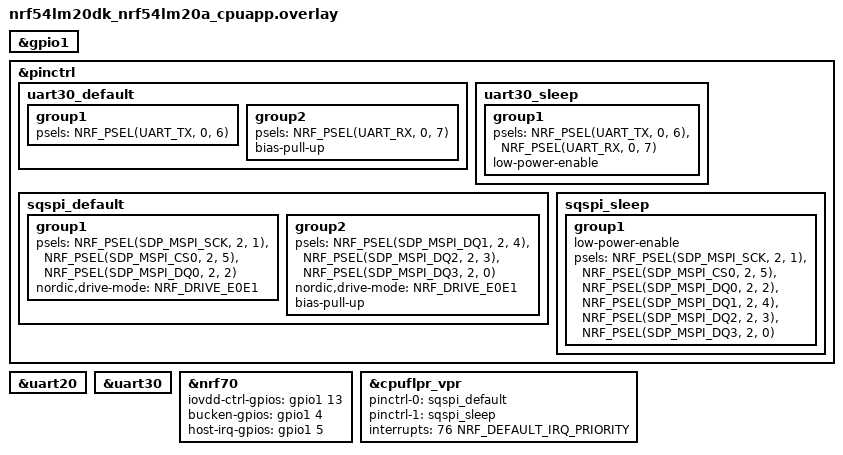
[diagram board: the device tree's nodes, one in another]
/*
 * Copyright (c) 2025 Nordic Semiconductor
 *
 * SPDX-License-Identifier: LicenseRef-Nordic-5-Clause
 */

/* APP core overlay - GPIO pins configuration for nRF70 */


&gpio1 {
	status = "okay";
};

&pinctrl {
	uart30_default: uart30_default {
		group1 {
			psels = <NRF_PSEL(UART_TX, 0, 6)>;
		};

		group2 {
			psels = <NRF_PSEL(UART_RX, 0, 7)>;
			bias-pull-up;
		};
	};

	uart30_sleep: uart30_sleep {
		group1 {
			psels = <NRF_PSEL(UART_TX, 0, 6)>,
				<NRF_PSEL(UART_RX, 0, 7)>;
			low-power-enable;
		};
	};
};

&uart20 {
	status = "okay";
};

&uart30 {
	status = "okay";
};

#include <freq.h>

&pinctrl {
	sqspi_default: sqspi_default {
		group1 {
			psels = <NRF_PSEL(SDP_MSPI_SCK, 2, 1)>,
				<NRF_PSEL(SDP_MSPI_CS0, 2, 5)>,
				<NRF_PSEL(SDP_MSPI_DQ0, 2, 2)>;
			nordic,drive-mode = <NRF_DRIVE_E0E1>;
		};
		group2 {
			psels = <NRF_PSEL(SDP_MSPI_DQ1, 2, 4)>,
				<NRF_PSEL(SDP_MSPI_DQ2, 2, 3)>,
				<NRF_PSEL(SDP_MSPI_DQ3, 2, 0)>;
			nordic,drive-mode = <NRF_DRIVE_E0E1>;
			bias-pull-up;
		};
	};

	sqspi_sleep: sqspi_sleep {
		group1 {
			low-power-enable;
			psels = <NRF_PSEL(SDP_MSPI_SCK, 2, 1)>,
				<NRF_PSEL(SDP_MSPI_CS0, 2, 5)>,
				<NRF_PSEL(SDP_MSPI_DQ0, 2, 2)>,
				<NRF_PSEL(SDP_MSPI_DQ1, 2, 4)>,
				<NRF_PSEL(SDP_MSPI_DQ2, 2, 3)>,
				<NRF_PSEL(SDP_MSPI_DQ3, 2, 0)>;
		};
	};
};

&nrf70 {
	iovdd-ctrl-gpios = <&gpio1 13 GPIO_ACTIVE_HIGH>;
	bucken-gpios = <&gpio1 4 GPIO_ACTIVE_HIGH>;
	host-irq-gpios = <&gpio1 5 GPIO_ACTIVE_HIGH>;
};

/* cpuflpr_vpr node needed for mspi_sqspi driver on APP core */
&cpuflpr_vpr {
	pinctrl-0 = <&sqspi_default>;
	pinctrl-1 = <&sqspi_sleep>;
	pinctrl-names = "default", "sleep";
	interrupts = <76 NRF_DEFAULT_IRQ_PRIORITY>;
	status = "okay";
};
